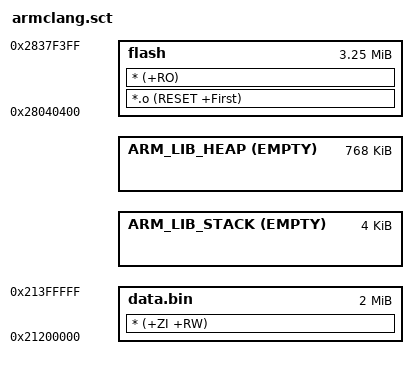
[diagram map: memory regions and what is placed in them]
#! armclang --target=arm-arm-none-eabi -march=armv8.1-m.main+mve.fp+fp.dp -E -x c
/*
 * Copyright (c) 2021-2024 Arm Limited. All rights reserved.
 *
 * Licensed under the Apache License, Version 2.0 (the "License");
 * you may not use this file except in compliance with the License.
 * You may obtain a copy of the License at
 *
 *     http://www.apache.org/licenses/LICENSE-2.0
 *
 * Unless required by applicable law or agreed to in writing, software
 * distributed under the License is distributed on an "AS IS" BASIS,
 * WITHOUT WARRANTIES OR CONDITIONS OF ANY KIND, either express or implied.
 * See the License for the specific language governing permissions and
 * limitations under the License.
 */

#define FLASH_NS_PARTITION_SIZE 0x340000
#define FLASH_S_PARTITION_SIZE  0x40000
#define ROM_START               0x28000000
#define BL2_HEADER_SIZE         0x400
#define BL2_TRAILER_SIZE        0xC00
#define ISRAM0_BASE_ADDRESS     0x21000000
#define ISRAM1_OFFSET           0x00200000
#define ISRAM1_SIZE             0x00200000
#define STACK_SIZE              0x00001000
#define HEAP_SIZE               0x000C0000


LOAD_REGION_0 (ROM_START + ((((0) + (FLASH_S_PARTITION_SIZE)) + BL2_HEADER_SIZE)))
{
    flash (ROM_START + ((((0) + (FLASH_S_PARTITION_SIZE)) + BL2_HEADER_SIZE))) (((FLASH_NS_PARTITION_SIZE) - BL2_HEADER_SIZE - BL2_TRAILER_SIZE)) {
        *.o (RESET +First)
        * (+RO)
    }

    data.bin (ISRAM0_BASE_ADDRESS + ((ISRAM1_OFFSET))) (ISRAM1_SIZE) {
        * (+ZI +RW)
    }


    ARM_LIB_STACK +0 ALIGN 32 EMPTY (STACK_SIZE) {
    }

    ARM_LIB_HEAP +0 ALIGN 8 EMPTY (HEAP_SIZE) {
    }
}
